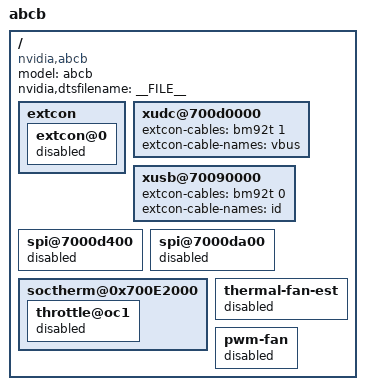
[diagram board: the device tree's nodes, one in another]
/*
 * arch/arm64/boot/dts/tegra210-abcb-01-00.dts
 *
 * Copyright (c) 2014-2016, NVIDIA CORPORATION.  All rights reserved.
 *
 * This program is free software; you can redistribute it and/or modify
 * it under the terms of the GNU General Public License as published by
 * the Free Software Foundation; version 2 of the License.
 *
 * This program is distributed in the hope that it will be useful, but WITHOUT
 * ANY WARRANTY; without even the implied warranty of MERCHANTABILITY or
 * FITNESS FOR A PARTICULAR PURPOSE.  See the GNU General Public License for
 * more details.
 *
 */

#include "tegra210-abcb-common.dtsi"
#include "tegra210-abcb-common-disp.dtsi"
#include "abca-platforms/tegra210-abcb-power-tree-01-00.dtsi"
#include "abca-platforms/tegra210-abcb-01-00-emc.dtsi"
#include "abca-platforms/tegra210-abca-powermon-05-00.dtsi"
#include "abca-platforms/tegra210-abcb-pinmux-01-00.dtsi"

/ {
	model = "abcb";
	compatible = "nvidia,abcb", "nvidia,tegra210";
	nvidia,dtsfilename = __FILE__;

	#address-cells = <2>;
	#size-cells = <2>;

	extcon {
		extcon@0 {
			status = "disabled";
		};
	};

	xudc@700d0000 {
		extcon-cables = <&bm92t 1>;
		extcon-cable-names = "vbus";
	};

	xusb@70090000 {
		extcon-cables = <&bm92t 0>;
		extcon-cable-names = "id";
	};

	spi@7000d400 {
		status = "disabled";
	};
	spi@7000da00 {
		status = "disabled";
	};

	soctherm@0x700E2000 {
		throttle@oc1 {
			status = "disabled";
		};
	};

	thermal-fan-est {
		status = "disabled";
	};

	pwm-fan {
		status = "disabled";
	};

	/delete-node/ psy_extcon_xudc;
	/delete-node/ psy_extcon;
	/delete-node/ usb_cd@7009f000;
};
